# MSP430FR5962 register map
File version: 2.1
Texas Instruments MSP430FR59xx Ultra-low power MCU
CPU: MSP430FR5962 r2p1, little endian, MPU, no FPU, 3 interrupt priority bits
Registers are 16-bit, read-write, reset 0x0 unless marked. A register's access mark holds for its fields unless they carry their own. Offsets are from the block's base; lines under a group give offsets from that group; [hi:lo] are bit positions; {n}, {i} and the like mark numbered series; 'fields as' and 'values as' point back to an identical list; <NAME> marks a mode.

## Memory map
0x00000100 SFR size 0xA
0x00000120 PMM size 0xA
0x00000140 FRCTL_A size 0xA
0x00000150 CRC size 0xA
0x00000158 RAMCTL size 0xA
0x0000015C WDT_A size 0xA
0x00000160 CS size 0xA
0x00000180 SYS size 0xA
0x000001B0 REF_A size 0xA
0x00000200 PA size 0xA
0x00000200 P{n} size 0xA (n=1..9)
0x00000200 PB size 0xA
0x00000200 PC size 0xA
0x00000200 PD size 0xA
0x00000200 PE size 0xA
0x00000200 PJ size 0xA
0x00000340 TA0 size 0xA
0x00000380 TA1 size 0xA
0x000003C0 TB0 size 0xA
0x00000400 TA2 size 0xA
0x00000430 CAPTIO0 size 0xA
0x00000440 TA3 size 0xA
0x00000470 CAPTIO1 size 0xA
0x000004A0 RTC_C size 0xA
0x000004C0 MPY32 size 0xA
0x00000500 DMA size 0xA
0x000005A0 MPU size 0xA
0x000005C0 eUSCI_A0 size 0xA
0x000005E0 eUSCI_A1 size 0xA
0x00000600 eUSCI_A2 size 0xA
0x00000620 eUSCI_A3 size 0xA
0x00000640 eUSCI_B0 size 0xA
0x00000680 eUSCI_B1 size 0xA
0x000006C0 eUSCI_B2 size 0xA
0x00000700 eUSCI_B3 size 0xA
0x000007C0 TA4 size 0xA
0x00000800 ADC12_B size 0xA
0x000008C0 COMP_E size 0xA
0x00000980 CRC32 size 0xA
0x000009C0 AES256 size 0xA
0x0000FF90 _INTERRUPTS

## Interrupts
19 PORT8 (_INTERRUPTS) — 0xFFB6
20 PORT7 (_INTERRUPTS) — 0xFFB8
21 EUSCI_B3 (_INTERRUPTS) — 0xFFBA
22 EUSCI_B2 (_INTERRUPTS) — 0xFFBC
23 EUSCI_B1 (_INTERRUPTS) — 0xFFBE
24 EUSCI_A3 (_INTERRUPTS) — 0xFFC0
25 EUSCI_A2 (_INTERRUPTS) — 0xFFC2
26 PORT6 (_INTERRUPTS) — 0xFFC4
27 PORT5 (_INTERRUPTS) — 0xFFC6
28 TIMER4_A1 (_INTERRUPTS) — 0xFFC8
29 TIMER4_A0 (_INTERRUPTS) — 0xFFCA
30 AES256 (_INTERRUPTS) — 0xFFCC
31 RTC_C (_INTERRUPTS) — 0xFFCE
32 PORT4 (_INTERRUPTS) — 0xFFD0
33 PORT3 (_INTERRUPTS) — 0xFFD2
34 TIMER3_A1 (_INTERRUPTS) — 0xFFD4
35 TIMER3_A0 (_INTERRUPTS) — 0xFFD6
36 PORT2 (_INTERRUPTS) — 0xFFD8
37 TIMER2_A1 (_INTERRUPTS) — 0xFFDA
38 TIMER2_A0 (_INTERRUPTS) — 0xFFDC
39 PORT1 (_INTERRUPTS) — 0xFFDE
40 TIMER1_A1 (_INTERRUPTS) — 0xFFE0
41 TIMER1_A0 (_INTERRUPTS) — 0xFFE2
42 DMA (_INTERRUPTS) — 0xFFE4
43 EUSCI_A1 (_INTERRUPTS) — 0xFFE6
44 TIMER0_A1 (_INTERRUPTS) — 0xFFE8
45 TIMER0_A0 (_INTERRUPTS) — 0xFFEA
46 ADC12_B (_INTERRUPTS) — 0xFFEC
47 EUSCI_B0 (_INTERRUPTS) — 0xFFEE
48 EUSCI_A0 (_INTERRUPTS) — 0xFFF0
49 WDT (_INTERRUPTS) — 0xFFF2
50 TIMER0_B1 (_INTERRUPTS) — 0xFFF4
51 TIMER0_B0 (_INTERRUPTS) — 0xFFF6
52 COMP_E (_INTERRUPTS) — 0xFFF8
53 UNMI (_INTERRUPTS) — 0xFFFA
54 SYSNMI (_INTERRUPTS) — 0xFFFC

## AES256
Base 0x000009C0
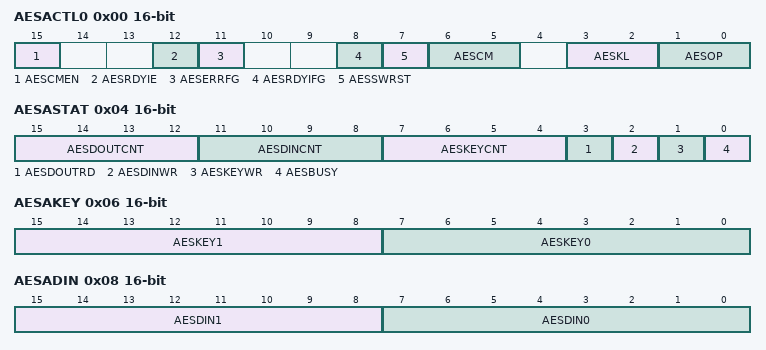
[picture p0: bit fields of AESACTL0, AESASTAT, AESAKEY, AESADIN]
0x00 AESACTL0 — AES Accelerator Control Register 0
  [15] AESCMEN — [15:15] AES cipher mode enable
    0=DISABLE (No DMA triggers are generated); 1=ENABLE (DMA ciphermode support operation is enabled and the corresponding DMA triggers are generated)
  [12] AESRDYIE — [12:12] AES ready interrupt enable
    0=DISABLE (Interrupt disabled); 1=ENABLE (Interrupt enabled)
  [11] AESERRFG — [11:11] AES error flag
    0=No error; 1=Error occurred
  [8] AESRDYIFG — [8:8] AES ready interrupt flag
    0=No interrupt pending; 1=Interrupt pending
  [7] AESSWRST — [7:7] AES software reset
    0=No reset; 1=RESET (Reset AES accelerator module)
  [6:5] AESCM — [6:5] AES cipher mode select
    0=ECB; 1=CBC; 2=OFB; 3=CFB
  [3:2] AESKL — [3:2] AES key length
    0=AES128. The key size is 128 bit; 1=AES192. The key size is 192 bit.; 2=AES256. The key size is 256 bit
  [1:0] AESOP — [1:0] AES operation
    0=Encryption; 1=Decryption. The provided key is the same key used for encryption; 2=Generate first round key required for decryption; 3=Decryption. The provided key is the first round key required for decryption
0x02 AESACTL1 — AES Accelerator Control Register 1
  [7:0] AESBLKCNT — [7:0] Cipher Block Counter
0x04 AESASTAT — AES Accelerator Status Register
  [15:12] AESDOUTCNT — [15:12] Bytes read via AESADOUT
  [11:8] AESDINCNT — [11:8] Bytes written via AESADIN, AESAXDIN or AESAXIN
  [7:4] AESKEYCNT — [7:4] Bytes written via AESAKEY for AESKL=00, half-words written via AESAKEY
  [3] AESDOUTRD — [3:3] All 16 bytes read from AESADOUT
    0=Not all bytes read; 1=All bytes read
  [2] AESDINWR — [2:2] All 16 bytes written to AESADIN, AESAXDIN or AESAXIN
    0=Not all bytes written; 1=All bytes written
  [1] AESKEYWR — [1:1] All 16 bytes written to AESAKEY
    0=Not all bytes written; 1=All bytes written
  [0] AESBUSY — [0:0] AES accelerator module busy
    0=IDLE (Not busy); 1=BUSY
0x06 AESAKEY — AES Accelerator Key Register
  [15:8] AESKEY1 — [15:8] AES key byte n+1 when AESAKEY is written as half-word
  [7:0] AESKEY0 — [7:0] AES key byte n when AESAKEY is written as half-word
0x08 AESADIN — AES Accelerator Data In Register
  [15:8] AESDIN1 — [15:8] AES data in byte n+1 when AESADIN is written as half-word
  [7:0] AESDIN0 — [7:0] AES data in byte n when AESADIN is written as half-word
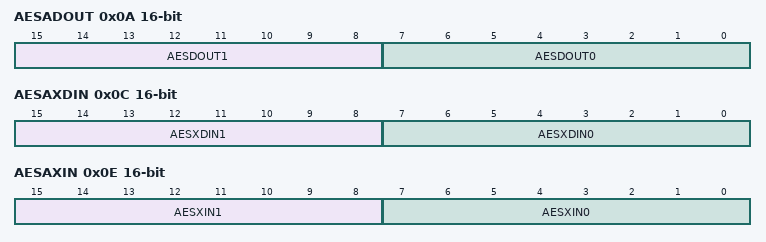
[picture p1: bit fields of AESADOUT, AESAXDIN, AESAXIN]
0x0A AESADOUT — AES Accelerator Data Out Register
  [15:8] AESDOUT1 — [15:8] AES data out byte n+1 when AESADOUT is read as half-word
  [7:0] AESDOUT0 — [7:0] AES data out byte n when AESADOUT is read as half-word
0x0C AESAXDIN — AES Accelerator XORed Data In Register
  [15:8] AESXDIN1 — [15:8] AES data in byte n+1 when AESAXDIN is written as half-word
  [7:0] AESXDIN0 — [7:0] AES data in byte n when AESAXDIN is written as half-word
0x0E AESAXIN — AES Accelerator XORed Data In Register
  [15:8] AESXIN1 — [15:8] AES data in byte n+1 when AESAXIN is written as half-word
  [7:0] AESXIN0 — [7:0] AES data in byte n when AESAXIN is written as half-word
